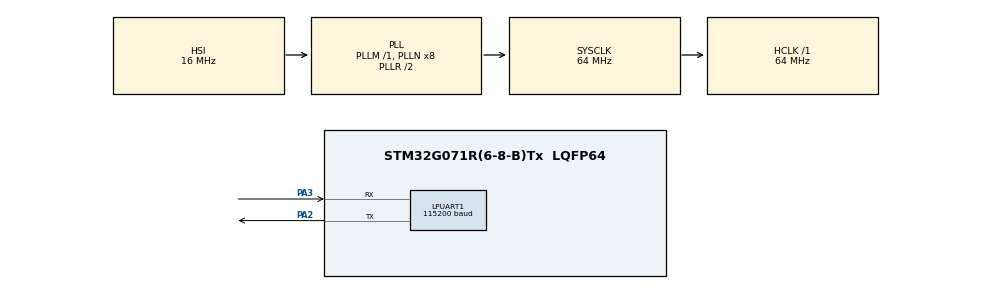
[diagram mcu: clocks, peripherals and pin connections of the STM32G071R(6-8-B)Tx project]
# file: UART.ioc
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LPUART1.BaudRate=115200
LPUART1.WordLength=UART_WORDLENGTH_8B
Mcu.Family=STM32G0
Mcu.Name=STM32G071R(6-8-B)Tx
Mcu.Package=LQFP64
PA2.Mode=Asynchronous
PA2.Signal=LPUART1_TX
PA3.Mode=Asynchronous
PA3.Signal=LPUART1_RX
ProjectManager.HeapSize=0x200
ProjectManager.StackSize=0x400
ProjectManager.TargetToolchain=MDK-ARM V5
RCC.ADCFreq_Value=64000000
RCC.AHBFreq_Value=64000000
RCC.CortexFreq_Value=64000000
RCC.EXTERNAL_CLOCK_VALUE=48000
RCC.HCLKFreq_Value=64000000
RCC.HSE_VALUE=8000000
RCC.HSI_VALUE=16000000
RCC.LSE_VALUE=32768
RCC.SYSCLKFreq_VALUE=64000000
RCC.SYSCLKSource=RCC_SYSCLKSOURCE_PLLCLK
RCC.VCOOutputFreq_Value=128000000
VP_SYS_VS_DBSignals.Mode=DisableDeadBatterySignals
board=custom

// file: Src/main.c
/* USER CODE BEGIN Header */
/**
  ******************************************************************************
  * @file           : main.c
  * @brief          : Main program body
  ******************************************************************************
  * @attention
  *
  * <h2><center>&copy; Copyright (c) 2019 STMicroelectronics.
  * All rights reserved.</center></h2>
  *
  * This software component is licensed by ST under BSD 3-Clause license,
  * the "License"; You may not use this file except in compliance with the
  * License. You may obtain a copy of the License at:
  *                        opensource.org/licenses/BSD-3-Clause
  *
  ******************************************************************************
  */
/* USER CODE END Header */

#include "main.h"

/* USER CODE BEGIN Includes */
#include <stdio.h>
/* USER CODE END Includes */

UART_HandleTypeDef hlpuart1;

void SystemClock_Config(void);
static void MX_GPIO_Init(void);
static void MX_LPUART1_UART_Init(void);
/* USER CODE BEGIN PFP */
#define PUTCHAR_PROTOTYPE int fputc(int ch,FILE *f)
/* USER CODE END PFP */

int main(void)
{

  /* MCU Configuration--------------------------------------------------------*/

  /* Reset of all peripherals, Initializes the Flash interface and the Systick. */
  HAL_Init();

  /* Configure the system clock */
  SystemClock_Config();

  /* USER CODE BEGIN SysInit */
	HAL_DeInit();
  /* USER CODE END SysInit */

  /* Initialize all configured peripherals */
  MX_GPIO_Init();
  MX_LPUART1_UART_Init();
  /* USER CODE BEGIN 2 */
	printf("hello world\r\n");
  /* USER CODE END 2 */

  /* Infinite loop */
  /* USER CODE BEGIN WHILE */
  while (1)
  {
		HAL_UART_Transmit(&hlpuart1,"Hlll",20,0);
		HAL_Delay(1000);
    /* USER CODE END WHILE */

  }
}

void SystemClock_Config(void)
{
  RCC_OscInitTypeDef RCC_OscInitStruct = {0};
  RCC_ClkInitTypeDef RCC_ClkInitStruct = {0};
  RCC_PeriphCLKInitTypeDef PeriphClkInit = {0};

  /** Configure the main internal regulator output voltage
  */
  HAL_PWREx_ControlVoltageScaling(PWR_REGULATOR_VOLTAGE_SCALE1);
  /** Initializes the CPU, AHB and APB busses clocks
  */
  RCC_OscInitStruct.OscillatorType = RCC_OSCILLATORTYPE_HSI;
  RCC_OscInitStruct.HSIState = RCC_HSI_ON;
  RCC_OscInitStruct.HSIDiv = RCC_HSI_DIV1;
  RCC_OscInitStruct.HSICalibrationValue = RCC_HSICALIBRATION_DEFAULT;
  RCC_OscInitStruct.PLL.PLLState = RCC_PLL_ON;
  RCC_OscInitStruct.PLL.PLLSource = RCC_PLLSOURCE_HSI;
  RCC_OscInitStruct.PLL.PLLM = RCC_PLLM_DIV1;
  RCC_OscInitStruct.PLL.PLLN = 8;
  RCC_OscInitStruct.PLL.PLLP = RCC_PLLP_DIV2;
  RCC_OscInitStruct.PLL.PLLQ = RCC_PLLQ_DIV2;
  RCC_OscInitStruct.PLL.PLLR = RCC_PLLR_DIV2;
  if (HAL_RCC_OscConfig(&RCC_OscInitStruct) != HAL_OK)
  {
    Error_Handler();
  }
  /** Initializes the CPU, AHB and APB busses clocks
  */
  RCC_ClkInitStruct.ClockType = RCC_CLOCKTYPE_HCLK|RCC_CLOCKTYPE_SYSCLK
                              |RCC_CLOCKTYPE_PCLK1;
  RCC_ClkInitStruct.SYSCLKSource = RCC_SYSCLKSOURCE_PLLCLK;
  RCC_ClkInitStruct.AHBCLKDivider = RCC_SYSCLK_DIV1;
  RCC_ClkInitStruct.APB1CLKDivider = RCC_HCLK_DIV1;

  if (HAL_RCC_ClockConfig(&RCC_ClkInitStruct, FLASH_LATENCY_2) != HAL_OK)
  {
    Error_Handler();
  }
  /** Initializes the peripherals clocks
  */
  PeriphClkInit.PeriphClockSelection = RCC_PERIPHCLK_LPUART1;
  PeriphClkInit.Lpuart1ClockSelection = RCC_LPUART1CLKSOURCE_PCLK1;
  if (HAL_RCCEx_PeriphCLKConfig(&PeriphClkInit) != HAL_OK)
  {
    Error_Handler();
  }
}

static void MX_LPUART1_UART_Init(void)
{

  hlpuart1.Instance = LPUART1;
  hlpuart1.Init.BaudRate = 115200;
  hlpuart1.Init.WordLength = UART_WORDLENGTH_8B;
  hlpuart1.Init.StopBits = UART_STOPBITS_1;
  hlpuart1.Init.Parity = UART_PARITY_NONE;
  hlpuart1.Init.Mode = UART_MODE_TX_RX;
  hlpuart1.Init.HwFlowCtl = UART_HWCONTROL_NONE;
  hlpuart1.Init.OneBitSampling = UART_ONE_BIT_SAMPLE_DISABLE;
  hlpuart1.Init.ClockPrescaler = UART_PRESCALER_DIV1;
  hlpuart1.AdvancedInit.AdvFeatureInit = UART_ADVFEATURE_NO_INIT;
  hlpuart1.FifoMode = UART_FIFOMODE_DISABLE;
  if (HAL_UART_Init(&hlpuart1) != HAL_OK)
  {
    Error_Handler();
  }
  if (HAL_UARTEx_SetTxFifoThreshold(&hlpuart1, UART_TXFIFO_THRESHOLD_1_8) != HAL_OK)
  {
    Error_Handler();
  }
  if (HAL_UARTEx_SetRxFifoThreshold(&hlpuart1, UART_RXFIFO_THRESHOLD_1_8) != HAL_OK)
  {
    Error_Handler();
  }
  if (HAL_UARTEx_DisableFifoMode(&hlpuart1) != HAL_OK)
  {
    Error_Handler();
  }

}

static void MX_GPIO_Init(void)
{

  /* GPIO Ports Clock Enable */
  __HAL_RCC_GPIOA_CLK_ENABLE();

}

/* USER CODE BEGIN 4 */
PUTCHAR_PROTOTYPE
{
	HAL_UART_Transmit(&hlpuart1,(uint8_t *) &ch,1,0xFFFF);
	return ch;
}

/* USER CODE END 4 */

void Error_Handler(void)
{
}

/************************ (C) COPYRIGHT STMicroelectronics *****END OF FILE****/
